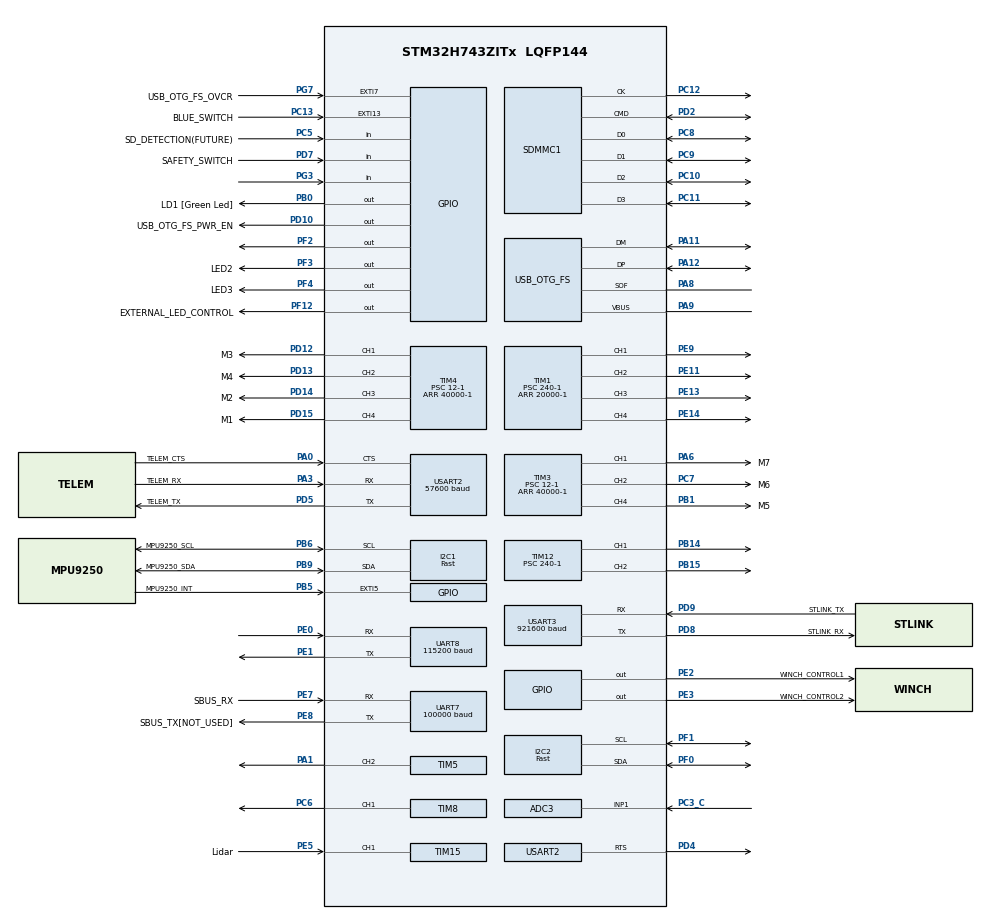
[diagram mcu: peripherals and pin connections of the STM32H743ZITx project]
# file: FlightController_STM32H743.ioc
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ADC3.Channel-1\#ChannelRegularConversion=ADC_CHANNEL_1
ADC3.ContinuousConvMode=ENABLE
ADC3.ConversionDataManagement=ADC_CONVERSIONDATA_DMA_CIRCULAR
ADC3.NbrOfConversionFlag=1
ADC3.OffsetNumber-1\#ChannelRegularConversion=ADC_OFFSET_NONE
ADC3.OffsetSignedSaturation-1\#ChannelRegularConversion=DISABLE
ADC3.Rank-1\#ChannelRegularConversion=1
ADC3.Resolution=ADC_RESOLUTION_12B
ADC3.SamplingTime-1\#ChannelRegularConversion=ADC_SAMPLETIME_1CYCLE_5
Bdma.ADC3.0.Direction=DMA_PERIPH_TO_MEMORY
Bdma.ADC3.0.EventEnable=DISABLE
Bdma.ADC3.0.Instance=BDMA_Channel0
Bdma.ADC3.0.MemDataAlignment=DMA_MDATAALIGN_HALFWORD
Bdma.ADC3.0.MemInc=DMA_MINC_ENABLE
Bdma.ADC3.0.Mode=DMA_CIRCULAR
Bdma.ADC3.0.PeriphDataAlignment=DMA_PDATAALIGN_HALFWORD
Bdma.ADC3.0.PeriphInc=DMA_PINC_DISABLE
Bdma.ADC3.0.Polarity=HAL_DMAMUX_REQ_GEN_RISING
Bdma.ADC3.0.Priority=DMA_PRIORITY_LOW
Bdma.ADC3.0.RequestNumber=1
Bdma.ADC3.0.SignalID=NONE
Bdma.ADC3.0.SyncEnable=DISABLE
Bdma.ADC3.0.SyncPolarity=HAL_DMAMUX_SYNC_NO_EVENT
Bdma.ADC3.0.SyncRequestNumber=1
Bdma.ADC3.0.SyncSignalID=NONE
Bdma.Request0=ADC3
Bdma.RequestsNb=1
Dma.I2C1_RX.1.Direction=DMA_PERIPH_TO_MEMORY
Dma.I2C1_RX.1.EventEnable=DISABLE
Dma.I2C1_RX.1.FIFOMode=DMA_FIFOMODE_DISABLE
Dma.I2C1_RX.1.Instance=DMA1_Stream2
Dma.I2C1_RX.1.MemDataAlignment=DMA_MDATAALIGN_BYTE
Dma.I2C1_RX.1.MemInc=DMA_MINC_ENABLE
Dma.I2C1_RX.1.Mode=DMA_NORMAL
Dma.I2C1_RX.1.PeriphDataAlignment=DMA_PDATAALIGN_BYTE
Dma.I2C1_RX.1.PeriphInc=DMA_PINC_DISABLE
Dma.I2C1_RX.1.Polarity=HAL_DMAMUX_REQ_GEN_RISING
Dma.I2C1_RX.1.Priority=DMA_PRIORITY_LOW
Dma.I2C1_RX.1.RequestNumber=1
Dma.I2C1_RX.1.SignalID=NONE
Dma.I2C1_RX.1.SyncEnable=DISABLE
Dma.I2C1_RX.1.SyncPolarity=HAL_DMAMUX_SYNC_NO_EVENT
Dma.I2C1_RX.1.SyncRequestNumber=1
Dma.I2C1_RX.1.SyncSignalID=NONE
Dma.I2C1_TX.3.Direction=DMA_MEMORY_TO_PERIPH
Dma.I2C1_TX.3.EventEnable=DISABLE
Dma.I2C1_TX.3.FIFOMode=DMA_FIFOMODE_DISABLE
Dma.I2C1_TX.3.Instance=DMA1_Stream3
Dma.I2C1_TX.3.MemDataAlignment=DMA_MDATAALIGN_BYTE
Dma.I2C1_TX.3.MemInc=DMA_MINC_ENABLE
Dma.I2C1_TX.3.Mode=DMA_NORMAL
Dma.I2C1_TX.3.PeriphDataAlignment=DMA_PDATAALIGN_BYTE
Dma.I2C1_TX.3.PeriphInc=DMA_PINC_DISABLE
Dma.I2C1_TX.3.Polarity=HAL_DMAMUX_REQ_GEN_RISING
Dma.I2C1_TX.3.Priority=DMA_PRIORITY_LOW
Dma.I2C1_TX.3.RequestNumber=1
Dma.I2C1_TX.3.SignalID=NONE
Dma.I2C1_TX.3.SyncEnable=DISABLE
Dma.I2C1_TX.3.SyncPolarity=HAL_DMAMUX_SYNC_NO_EVENT
Dma.I2C1_TX.3.SyncRequestNumber=1
Dma.I2C1_TX.3.SyncSignalID=NONE
Dma.Request0=UART7_RX
Dma.Request1=I2C1_RX
Dma.Request2=UART8_RX
Dma.Request3=I2C1_TX
Dma.Request4=USART2_RX
Dma.Request5=USART2_TX
Dma.UART7_RX.0.Direction=DMA_PERIPH_TO_MEMORY
Dma.UART7_RX.0.EventEnable=DISABLE
Dma.UART7_RX.0.FIFOMode=DMA_FIFOMODE_DISABLE
Dma.UART7_RX.0.Instance=DMA1_Stream1
Dma.UART7_RX.0.MemDataAlignment=DMA_MDATAALIGN_BYTE
Dma.UART7_RX.0.MemInc=DMA_MINC_ENABLE
Dma.UART7_RX.0.Mode=DMA_CIRCULAR
Dma.UART7_RX.0.PeriphDataAlignment=DMA_PDATAALIGN_BYTE
Dma.UART7_RX.0.PeriphInc=DMA_PINC_DISABLE
Dma.UART7_RX.0.Polarity=HAL_DMAMUX_REQ_GEN_RISING
Dma.UART7_RX.0.Priority=DMA_PRIORITY_LOW
Dma.UART7_RX.0.RequestNumber=1
Dma.UART7_RX.0.SignalID=NONE
Dma.UART7_RX.0.SyncEnable=DISABLE
Dma.UART7_RX.0.SyncPolarity=HAL_DMAMUX_SYNC_NO_EVENT
Dma.UART7_RX.0.SyncRequestNumber=1
Dma.UART7_RX.0.SyncSignalID=NONE
Dma.UART8_RX.2.Direction=DMA_PERIPH_TO_MEMORY
Dma.UART8_RX.2.EventEnable=DISABLE
Dma.UART8_RX.2.FIFOMode=DMA_FIFOMODE_DISABLE
Dma.UART8_RX.2.Instance=DMA1_Stream0
Dma.UART8_RX.2.MemDataAlignment=DMA_MDATAALIGN_BYTE
Dma.UART8_RX.2.MemInc=DMA_MINC_ENABLE
Dma.UART8_RX.2.Mode=DMA_CIRCULAR
Dma.UART8_RX.2.PeriphDataAlignment=DMA_PDATAALIGN_BYTE
Dma.UART8_RX.2.PeriphInc=DMA_PINC_DISABLE
Dma.UART8_RX.2.Polarity=HAL_DMAMUX_REQ_GEN_RISING
Dma.UART8_RX.2.Priority=DMA_PRIORITY_LOW
Dma.UART8_RX.2.RequestNumber=1
Dma.UART8_RX.2.SignalID=NONE
Dma.UART8_RX.2.SyncEnable=DISABLE
Dma.UART8_RX.2.SyncPolarity=HAL_DMAMUX_SYNC_NO_EVENT
Dma.UART8_RX.2.SyncRequestNumber=1
Dma.UART8_RX.2.SyncSignalID=NONE
Dma.USART2_RX.4.Direction=DMA_PERIPH_TO_MEMORY
Dma.USART2_RX.4.EventEnable=DISABLE
Dma.USART2_RX.4.FIFOMode=DMA_FIFOMODE_DISABLE
Dma.USART2_RX.4.Instance=DMA1_Stream4
Dma.USART2_RX.4.MemDataAlignment=DMA_MDATAALIGN_BYTE
Dma.USART2_RX.4.MemInc=DMA_MINC_ENABLE
Dma.USART2_RX.4.Mode=DMA_NORMAL
Dma.USART2_RX.4.PeriphDataAlignment=DMA_PDATAALIGN_BYTE
Dma.USART2_RX.4.PeriphInc=DMA_PINC_DISABLE
Dma.USART2_RX.4.Polarity=HAL_DMAMUX_REQ_GEN_RISING
Dma.USART2_RX.4.Priority=DMA_PRIORITY_LOW
Dma.USART2_RX.4.RequestNumber=1
Dma.USART2_RX.4.SignalID=NONE
Dma.USART2_RX.4.SyncEnable=DISABLE
Dma.USART2_RX.4.SyncPolarity=HAL_DMAMUX_SYNC_NO_EVENT
Dma.USART2_RX.4.SyncRequestNumber=1
Dma.USART2_RX.4.SyncSignalID=NONE
Dma.USART2_TX.5.Direction=DMA_MEMORY_TO_PERIPH
Dma.USART2_TX.5.EventEnable=DISABLE
Dma.USART2_TX.5.FIFOMode=DMA_FIFOMODE_DISABLE
Dma.USART2_TX.5.Instance=DMA1_Stream5
Dma.USART2_TX.5.MemDataAlignment=DMA_MDATAALIGN_BYTE
Dma.USART2_TX.5.MemInc=DMA_MINC_ENABLE
Dma.USART2_TX.5.Mode=DMA_NORMAL
Dma.USART2_TX.5.PeriphDataAlignment=DMA_PDATAALIGN_BYTE
Dma.USART2_TX.5.PeriphInc=DMA_PINC_DISABLE
Dma.USART2_TX.5.Polarity=HAL_DMAMUX_REQ_GEN_RISING
Dma.USART2_TX.5.Priority=DMA_PRIORITY_LOW
Dma.USART2_TX.5.RequestNumber=1
Dma.USART2_TX.5.SignalID=NONE
Dma.USART2_TX.5.SyncEnable=DISABLE
Dma.USART2_TX.5.SyncPolarity=HAL_DMAMUX_SYNC_NO_EVENT
Dma.USART2_TX.5.SyncRequestNumber=1
Dma.USART2_TX.5.SyncSignalID=NONE
FATFS.BSP.number=1
FATFS0.BSP.STBoard=false
FATFS0.BSP.api=Unknown
FATFS0.BSP.i2caddr=0
FATFS0.BSP.instance=PC5
FATFS0.BSP.ip=GPIO
FATFS0.BSP.mode=Input
FATFS0.BSP.name=Detect_SDIO
FATFS0.BSP.solution=PC5
FREERTOS.Tasks01=defaultTask,24,128,StartDefaultTask,Default,NULL,Dynamic,NULL,NULL;MPU9250_Task,48,256,MPU9250_StartTask,As external,NULL,Static,MPU9250_TaskBuffer,MPU9250_TaskControlBlock;BME280_Task,48,256,BME280_StartTask,As external,NULL,Static,BME280_TaskBuffer,BME280_TaskControlBlock;IST8310_Task,48,256,IST8310_StartTask,As external,NULL,Static,IST8310_TaskBuffer,IST8310_TaskControlBlock;SD_Task,24,2048,SD_StartTask,As external,NULL,Static,SD_TaskBuffer,SD_TaskControlBlock;AHRS_Task,48,256,AHRS_StartTask,As external,NULL,Static,AHRS_TaskBuffer,AHRS_TaskControlBlock;Commander_Task,48,256,Commander_StartTask,As external,NULL,Static,Commander_TaskBuffer,Commander_TaskControlBlock;Debug_Task,32,512,Debug_StartTask,As external,NULL,Dynamic,NULL,NULL;Buzzer_Task,32,256,Buzzer_StartTask,As external,NULL,Static,Buzzer_TaskBuffer,Buzzer_TaskControlBlock;Health_Task,48,512,Health_StartTask,As external,NULL,Static,Health_TaskBuffer,Health_TaskControlBlock;AC_Task,48,512,AC_StartTask,As external,NULL,Static,AC_TaskBuffer,AC_TaskControlBlock;INS_Task,47,2048,INS_StartTask,As external,NULL,Dynamic,NULL,NULL;PC_Task,47,1024,PC_StartTask,As external,NULL,Static,PC_TaskBuffer,PC_TaskControlBlock;GCS_Task,26,1024,GCS_StartTask,As external,NULL,Static,GCS_TaskBuffer,GCS_TaskControlBlock;AUTO_Task,47,1024,AUTO_StartTask,As external,NULL,Dynamic,NULL,NULL;SBUS_Task,48,512,SBUS_StartTask,As external,NULL,Static,SBUS_TaskBuffer,SBUS_TaskControlBlock;GPS_Task,48,512,GPS_StartTask,As external,NULL,Static,GPS_TaskBuffer,GPS_TaskControlBlock;MS4525D_Task,48,1024,MS4525D_StartTask,As external,NULL,Static,MS4525D_TaskBuffer,MS4525D_TaskControlBlock
FREERTOS.configTOTAL_HEAP_SIZE=30000
I2C1.I2C_Speed_Mode=I2C_Fast
I2C1.Timing=0x00B03FDB
I2C2.I2C_Speed_Mode=I2C_Fast
I2C2.Timing=0x00B03FDB
Mcu.Family=STM32H7
Mcu.Name=STM32H743ZITx
Mcu.Package=LQFP144
NVIC.ADC3_IRQn=true\:10\:0\:true\:false\:true\:true\:true\:true
NVIC.BDMA_Channel0_IRQn=true\:0\:0\:false\:false\:true\:true\:false\:true
NVIC.DMA1_Stream0_IRQn=true\:10\:0\:true\:false\:true\:true\:false\:true
NVIC.DMA1_Stream1_IRQn=true\:10\:0\:true\:false\:true\:true\:false\:true
NVIC.DMA1_Stream2_IRQn=true\:5\:0\:true\:false\:true\:true\:false\:true
NVIC.DMA1_Stream3_IRQn=true\:5\:0\:true\:false\:true\:true\:false\:true
NVIC.DMA1_Stream4_IRQn=true\:10\:0\:true\:false\:true\:true\:false\:true
NVIC.DMA1_Stream5_IRQn=true\:9\:0\:true\:false\:true\:true\:false\:true
NVIC.EXTI15_10_IRQn=true\:10\:0\:true\:false\:true\:false\:true\:true
NVIC.EXTI9_5_IRQn=true\:10\:0\:true\:false\:true\:false\:true\:true
NVIC.I2C1_ER_IRQn=true\:5\:0\:true\:false\:true\:false\:true\:true
NVIC.I2C1_EV_IRQn=true\:5\:0\:true\:false\:true\:false\:true\:true
NVIC.I2C2_ER_IRQn=true\:6\:0\:true\:false\:true\:false\:true\:true
NVIC.I2C2_EV_IRQn=true\:6\:0\:true\:false\:true\:false\:true\:true
NVIC.PriorityGroup=NVIC_PRIORITYGROUP_4
NVIC.SDMMC1_IRQn=true\:10\:0\:true\:false\:true\:false\:true\:true
NVIC.TIM15_IRQn=true\:0\:0\:false\:false\:true\:false\:true\:true
NVIC.TIM2_IRQn=true\:10\:0\:true\:false\:true\:false\:true\:true
NVIC.TIM6_DAC_IRQn=true\:0\:0\:false\:false\:true\:false\:false\:true
NVIC.TimeBase=TIM6_DAC_IRQn
NVIC.TimeBaseIP=TIM6
NVIC.UART7_IRQn=true\:10\:0\:true\:false\:true\:false\:true\:true
NVIC.UART8_IRQn=true\:8\:0\:true\:false\:true\:true\:true\:true
NVIC.USART2_IRQn=true\:10\:0\:true\:false\:true\:false\:true\:true
NVIC.USART3_IRQn=true\:0\:0\:false\:false\:true\:false\:true\:true
PA0.GPIO_Label=TELEM_CTS
PA0.Mode=CTS_RTS
PA0.Signal=USART2_CTS
PA1.Signal=S_TIM5_CH2
PA11.Mode=Device_Only
PA11.Signal=USB_OTG_FS_DM
PA12.Mode=Device_Only
PA12.Signal=USB_OTG_FS_DP
PA3.GPIO_Label=TELEM_RX
PA3.Mode=Asynchronous
PA3.Signal=USART2_RX
PA6.GPIO_Label=M7
PA6.Signal=S_TIM3_CH1
PA8.Mode=Activate_SOF_FS
PA8.Signal=USB_OTG_FS_SOF
PA9.Mode=Activate_VBUS
PA9.Signal=USB_OTG_FS_VBUS
PB0.GPIO_Label=LD1 [Green Led]
PB0.Signal=GPIO_Output
PB1.GPIO_Label=M5
PB1.Signal=S_TIM3_CH4
PB14.Signal=S_TIM12_CH1
PB15.Signal=S_TIM12_CH2
PB5.GPIO_Label=MPU9250_INT
PB5.GPIO_ModeDefaultEXTI=GPIO_MODE_IT_FALLING
PB5.GPIO_PuPd=GPIO_NOPULL
PB5.Signal=GPXTI5
PB6.GPIO_Label=MPU9250_SCL
PB6.Mode=I2C
PB6.Signal=I2C1_SCL
PB9.GPIO_Label=MPU9250_SDA
PB9.Mode=I2C
PB9.Signal=I2C1_SDA
PC10.GPIO_PuPd=GPIO_PULLUP
PC10.Mode=SD_4_bits_Wide_bus
PC10.Signal=SDMMC1_D2
PC11.GPIO_PuPd=GPIO_PULLUP
PC11.Mode=SD_4_bits_Wide_bus
PC11.Signal=SDMMC1_D3
PC12.Mode=SD_4_bits_Wide_bus
PC12.Signal=SDMMC1_CK
PC13.GPIO_Label=BLUE_SWITCH
PC13.Signal=GPXTI13
PC14-OSC32_IN\ (OSC32_IN).Mode=LSE-External-Clock-Source
PC14-OSC32_IN\ (OSC32_IN).Signal=RCC_OSC32_IN
PC3_C.Mode=IN1-Single-Ended
PC3_C.Signal=ADC3_INP1
PC5.GPIO_Label=SD_DETECTION(FUTURE)
PC5.Signal=GPIO_Input
PC6.Signal=S_TIM8_CH1
PC7.GPIO_Label=M6
PC7.Signal=S_TIM3_CH2
PC8.GPIO_PuPd=GPIO_PULLUP
PC8.Mode=SD_4_bits_Wide_bus
PC8.Signal=SDMMC1_D0
PC9.GPIO_PuPd=GPIO_PULLUP
PC9.Mode=SD_4_bits_Wide_bus
PC9.Signal=SDMMC1_D1
PD10.GPIO_Label=USB_OTG_FS_PWR_EN
PD10.Signal=GPIO_Output
PD12.GPIO_Label=M3
PD12.Signal=S_TIM4_CH1
PD13.GPIO_Label=M4
PD13.Signal=S_TIM4_CH2
PD14.GPIO_Label=M2
PD14.Signal=S_TIM4_CH3
PD15.GPIO_Label=M1
PD15.Signal=S_TIM4_CH4
PD2.GPIO_PuPd=GPIO_PULLUP
PD2.Mode=SD_4_bits_Wide_bus
PD2.Signal=SDMMC1_CMD
PD4.Mode=CTS_RTS
PD4.Signal=USART2_RTS
PD5.GPIO_Label=TELEM_TX
PD5.Mode=Asynchronous
PD5.Signal=USART2_TX
PD7.GPIO_Label=SAFETY_SWITCH
PD7.Signal=GPIO_Input
PD8.GPIO_Label=STLINK_RX
PD8.Mode=Asynchronous
PD8.Signal=USART3_TX
PD9.GPIO_Label=STLINK_TX
PD9.Mode=Asynchronous
PD9.Signal=USART3_RX
PE0.Mode=Asynchronous
PE0.Signal=UART8_RX
PE1.Mode=Asynchronous
PE1.Signal=UART8_TX
PE11.GPIO_Speed=GPIO_SPEED_FREQ_LOW
PE11.Signal=S_TIM1_CH2
PE13.Signal=S_TIM1_CH3
PE14.Signal=S_TIM1_CH4
PE2.GPIO_Label=WINCH_CONTROL1
PE2.Signal=GPIO_Output
PE3.GPIO_Label=WINCH_CONTROL2
PE3.Signal=GPIO_Output
PE5.GPIO_Label=Lidar
PE5.Signal=S_TIM15_CH1
PE7.GPIO_Label=SBUS_RX
PE7.Mode=Asynchronous
PE7.Signal=UART7_RX
PE8.GPIO_Label=SBUS_TX[NOT_USED]
PE8.Mode=Asynchronous
PE8.Signal=UART7_TX
PE9.Signal=S_TIM1_CH1
PF0.Mode=I2C
PF0.Signal=I2C2_SDA
PF1.Mode=I2C
PF1.Signal=I2C2_SCL
PF12.GPIO_Label=EXTERNAL_LED_CONTROL
PF12.Signal=GPIO_Output
PF2.Signal=GPIO_Output
PF3.GPIO_Label=LED2
PF3.Signal=GPIO_Output
PF4.GPIO_Label=LED3
PF4.Signal=GPIO_Output
PG3.Signal=GPIO_Input
PG7.GPIO_Label=USB_OTG_FS_OVCR
PG7.Signal=GPXTI7
PH0-OSC_IN\ (PH0).Mode=HSE-External-Oscillator
PH0-OSC_IN\ (PH0).Signal=RCC_OSC_IN
PH1-OSC_OUT\ (PH1).Mode=HSE-External-Oscillator
PH1-OSC_OUT\ (PH1).Signal=RCC_OSC_OUT
ProjectManager.HeapSize=0x200
ProjectManager.StackSize=0x400
ProjectManager.TargetToolchain=STM32CubeIDE
RCC.ADCFreq_Value=76000000
RCC.APB1Freq_Value=120000000
RCC.APB2Freq_Value=120000000
RCC.APB3Freq_Value=120000000
RCC.APB4Freq_Value=120000000
RCC.CortexFreq_Value=480000000
RCC.D1PPRE=RCC_APB3_DIV2
RCC.D2PPRE1=RCC_APB1_DIV2
RCC.D2PPRE2=RCC_APB2_DIV2
RCC.D3PPRE=RCC_APB4_DIV2
RCC.DIVM1=1
RCC.DIVM2=1
RCC.DIVN1=120
RCC.DIVN2=19
RCC.DIVQ1=20
RCC.HCLKFreq_Value=240000000
RCC.HPRE=RCC_HCLK_DIV2
RCC.HSE_VALUE=8000000
RCC.PLL2FRACN=0
RCC.PLL3FRACN=0
RCC.PLLFRACN=0
RCC.SYSCLKFreq_VALUE=480000000
RCC.SYSCLKSource=RCC_SYSCLKSOURCE_PLLCLK
RCC.USBFreq_Value=48000000
SDMMC1.ClockDiv=2
SH.S_TIM12_CH1.0=TIM12_CH1,PWM Generation1 CH1
SH.S_TIM12_CH2.0=TIM12_CH2,PWM Generation2 CH2
SH.S_TIM15_CH1.0=TIM15_CH1,Input_Capture1_from_TI1
SH.S_TIM15_CH1.1=TIM15_CH1,Input_Capture2_from_TI1
SH.S_TIM1_CH1.0=TIM1_CH1,PWM Generation1 CH1
SH.S_TIM1_CH2.0=TIM1_CH2,PWM Generation2 CH2
SH.S_TIM1_CH3.0=TIM1_CH3,PWM Generation3 CH3
SH.S_TIM1_CH4.0=TIM1_CH4,PWM Generation4 CH4
SH.S_TIM3_CH1.0=TIM3_CH1,PWM Generation1 CH1
SH.S_TIM3_CH2.0=TIM3_CH2,PWM Generation2 CH2
SH.S_TIM3_CH4.0=TIM3_CH4,PWM Generation4 CH4
SH.S_TIM4_CH1.0=TIM4_CH1,PWM Generation1 CH1
SH.S_TIM4_CH2.0=TIM4_CH2,PWM Generation2 CH2
SH.S_TIM4_CH3.0=TIM4_CH3,PWM Generation3 CH3
SH.S_TIM4_CH4.0=TIM4_CH4,PWM Generation4 CH4
SH.S_TIM5_CH2.0=TIM5_CH2,PWM Generation2 CH2
SH.S_TIM8_CH1.0=TIM8_CH1,PWM Generation1 CH1
TIM1.AutoReloadPreload=TIM_AUTORELOAD_PRELOAD_ENABLE
TIM1.Channel-PWM\ Generation1\ CH1=TIM_CHANNEL_1
TIM1.Channel-PWM\ Generation2\ CH2=TIM_CHANNEL_2
TIM1.Channel-PWM\ Generation3\ CH3=TIM_CHANNEL_3
TIM1.Channel-PWM\ Generation4\ CH4=TIM_CHANNEL_4
TIM1.OCFastMode_PWM-PWM\ Generation3\ CH3=TIM_OCFAST_DISABLE
TIM1.OCFastMode_PWM-PWM\ Generation4\ CH4=TIM_OCFAST_DISABLE
TIM1.Period=20000-1
TIM1.Prescaler=240-1
TIM12.AutoReloadPreload=TIM_AUTORELOAD_PRELOAD_ENABLE
TIM12.Channel-PWM\ Generation1\ CH1=TIM_CHANNEL_1
TIM12.Channel-PWM\ Generation2\ CH2=TIM_CHANNEL_2
TIM12.Period=20000-1
TIM12.Prescaler=240-1
TIM15.Channel-Input_Capture1_from_TI1=TIM_CHANNEL_1
TIM15.Channel-Input_Capture2_from_TI1=TIM_CHANNEL_2
TIM15.ICFilter_CH1=15
TIM15.ICPolarity_CH2=TIM_INPUTCHANNELPOLARITY_FALLING
TIM15.Period=65535-1
TIM15.Prescaler=240-1
TIM2.Prescaler=240-1
TIM3.AutoReloadPreload=TIM_AUTORELOAD_PRELOAD_DISABLE
TIM3.Channel-PWM\ Generation1\ CH1=TIM_CHANNEL_1
TIM3.Channel-PWM\ Generation2\ CH2=TIM_CHANNEL_2
TIM3.Channel-PWM\ Generation4\ CH4=TIM_CHANNEL_4
TIM3.OCFastMode_PWM-PWM\ Generation1\ CH1=TIM_OCFAST_DISABLE
TIM3.OCFastMode_PWM-PWM\ Generation2\ CH2=TIM_OCFAST_DISABLE
TIM3.OCFastMode_PWM-PWM\ Generation4\ CH4=TIM_OCFAST_DISABLE
TIM3.Period=40000-1
TIM3.Prescaler=12-1
TIM4.AutoReloadPreload=TIM_AUTORELOAD_PRELOAD_DISABLE
TIM4.Channel-PWM\ Generation1\ CH1=TIM_CHANNEL_1
TIM4.Channel-PWM\ Generation2\ CH2=TIM_CHANNEL_2
TIM4.Channel-PWM\ Generation3\ CH3=TIM_CHANNEL_3
TIM4.Channel-PWM\ Generation4\ CH4=TIM_CHANNEL_4
TIM4.OCFastMode_PWM-PWM\ Generation1\ CH1=TIM_OCFAST_DISABLE
TIM4.OCFastMode_PWM-PWM\ Generation2\ CH2=TIM_OCFAST_DISABLE
TIM4.OCFastMode_PWM-PWM\ Generation3\ CH3=TIM_OCFAST_DISABLE
TIM4.OCFastMode_PWM-PWM\ Generation4\ CH4=TIM_OCFAST_DISABLE
TIM4.Period=40000-1
TIM4.Prescaler=12-1
TIM5.Channel-PWM\ Generation2\ CH2=TIM_CHANNEL_2
TIM5.Period=10-1
TIM5.Prescaler=0
TIM5.Pulse-PWM\ Generation2\ CH2=5
TIM8.Channel-PWM\ Generation1\ CH1=TIM_CHANNEL_1
TIM8.Channel-PWM\ Generation2\ CH2=TIM_CHANNEL_2
TIM8.Period=40000-1
TIM8.Prescaler=12-1
UART7.BaudRate=100000
UART7.Parity=PARITY_EVEN
UART7.StopBits=UART_STOPBITS_2
UART7.WordLength=WORDLENGTH_9B
UART8.BaudRate=115200
USART2.BaudRate=57600
USART2.OverrunDisableParam=ADVFEATURE_OVERRUN_ENABLE
USART2.VirtualMode-Asynchronous=VM_ASYNC
USART3.BaudRate=921600
USART3.VirtualMode-Asynchronous=VM_ASYNC
USB_OTG_FS.VirtualMode=Device_Only
VP_FATFS_VS_SDIO.Mode=SDIO
VP_FREERTOS_VS_CMSIS_V2.Mode=CMSIS_V2
VP_SYS_VS_tim6.Mode=TIM6
VP_TIM1_VS_ClockSourceINT.Mode=Internal
VP_TIM2_VS_ClockSourceINT.Mode=Internal
VP_TIM3_VS_ClockSourceINT.Mode=Internal
VP_TIM4_VS_ClockSourceINT.Mode=Internal
VP_TIM5_VS_ClockSourceINT.Mode=Internal
VP_TIM8_VS_ClockSourceINT.Mode=Internal
board=NUCLEO-H743ZI2

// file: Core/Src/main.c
/* USER CODE BEGIN Header */
/**
  ******************************************************************************
  * @file           : main.c
  * @brief          : Main program body
  ******************************************************************************
  * @attention
  *
  * <h2><center>&copy; Copyright (c) 2020 STMicroelectronics.
  * All rights reserved.</center></h2>
  *
  * This software component is licensed by ST under Ultimate Liberty license
  * SLA0044, the "License"; You may not use this file except in compliance with
  * the License. You may obtain a copy of the License at:
  *                             www.st.com/SLA0044
  *
  ******************************************************************************
  */
/* USER CODE END Header */
#include "main.h"
#include "cmsis_os.h"
#include "adc.h"
#include "bdma.h"
#include "dma.h"
#include "fatfs.h"
#include "i2c.h"
#include "sdmmc.h"
#include "tim.h"
#include "usart.h"
#include "usb_otg.h"
#include "gpio.h"

/* USER CODE BEGIN Includes */
#include "Usec.h"
/* USER CODE END Includes */

void SystemClock_Config(void);
void MX_FREERTOS_Init(void);

int main(void)
{

  /* MCU Configuration--------------------------------------------------------*/

  /* Reset of all peripherals, Initializes the Flash interface and the Systick. */
  HAL_Init();

  /* Configure the system clock */
  SystemClock_Config();

  /* Initialize all configured peripherals */
  MX_GPIO_Init();
  MX_BDMA_Init();
  MX_DMA_Init();
  MX_USART3_UART_Init();
  MX_USB_OTG_FS_PCD_Init();
  MX_I2C1_Init();
  MX_I2C2_Init();
  MX_SDMMC1_SD_Init();
  MX_TIM3_Init();
  MX_TIM4_Init();
  MX_UART7_Init();
  MX_USART2_UART_Init();
  MX_FATFS_Init();
  MX_ADC3_Init();
  MX_TIM2_Init();
  MX_TIM1_Init();
  MX_UART8_Init();
  MX_TIM5_Init();
  MX_TIM8_Init();
  MX_TIM15_Init();
  MX_TIM12_Init();
  /* USER CODE BEGIN 2 */

  cppMain();
  /* USER CODE END 2 */

  /* Init scheduler */
  osKernelInitialize();  /* Call init function for freertos objects (in freertos.c) */
  MX_FREERTOS_Init();
  /* Start scheduler */
  osKernelStart();

  /* We should never get here as control is now taken by the scheduler */
  /* Infinite loop */
  while (1)
  {

  }
}

void SystemClock_Config(void)
{
  RCC_OscInitTypeDef RCC_OscInitStruct = {0};
  RCC_ClkInitTypeDef RCC_ClkInitStruct = {0};
  RCC_PeriphCLKInitTypeDef PeriphClkInitStruct = {0};

  /** Supply configuration update enable
  */
  HAL_PWREx_ConfigSupply(PWR_LDO_SUPPLY);
  /** Configure the main internal regulator output voltage
  */
  __HAL_PWR_VOLTAGESCALING_CONFIG(PWR_REGULATOR_VOLTAGE_SCALE0);

  while(!__HAL_PWR_GET_FLAG(PWR_FLAG_VOSRDY)) {}
  /** Macro to configure the PLL clock source
  */
  __HAL_RCC_PLL_PLLSOURCE_CONFIG(RCC_PLLSOURCE_HSE);
  /** Initializes the RCC Oscillators according to the specified parameters
  * in the RCC_OscInitTypeDef structure.
  */
  RCC_OscInitStruct.OscillatorType = RCC_OSCILLATORTYPE_HSE;
  RCC_OscInitStruct.HSEState = RCC_HSE_ON;
  RCC_OscInitStruct.PLL.PLLState = RCC_PLL_ON;
  RCC_OscInitStruct.PLL.PLLSource = RCC_PLLSOURCE_HSE;
  RCC_OscInitStruct.PLL.PLLM = 1;
  RCC_OscInitStruct.PLL.PLLN = 120;
  RCC_OscInitStruct.PLL.PLLP = 2;
  RCC_OscInitStruct.PLL.PLLQ = 20;
  RCC_OscInitStruct.PLL.PLLR = 2;
  RCC_OscInitStruct.PLL.PLLRGE = RCC_PLL1VCIRANGE_3;
  RCC_OscInitStruct.PLL.PLLVCOSEL = RCC_PLL1VCOWIDE;
  RCC_OscInitStruct.PLL.PLLFRACN = 0;
  if (HAL_RCC_OscConfig(&RCC_OscInitStruct) != HAL_OK)
  {
    Error_Handler();
  }
  /** Initializes the CPU, AHB and APB buses clocks
  */
  RCC_ClkInitStruct.ClockType = RCC_CLOCKTYPE_HCLK|RCC_CLOCKTYPE_SYSCLK
                              |RCC_CLOCKTYPE_PCLK1|RCC_CLOCKTYPE_PCLK2
                              |RCC_CLOCKTYPE_D3PCLK1|RCC_CLOCKTYPE_D1PCLK1;
  RCC_ClkInitStruct.SYSCLKSource = RCC_SYSCLKSOURCE_PLLCLK;
  RCC_ClkInitStruct.SYSCLKDivider = RCC_SYSCLK_DIV1;
  RCC_ClkInitStruct.AHBCLKDivider = RCC_HCLK_DIV2;
  RCC_ClkInitStruct.APB3CLKDivider = RCC_APB3_DIV2;
  RCC_ClkInitStruct.APB1CLKDivider = RCC_APB1_DIV2;
  RCC_ClkInitStruct.APB2CLKDivider = RCC_APB2_DIV2;
  RCC_ClkInitStruct.APB4CLKDivider = RCC_APB4_DIV2;

  if (HAL_RCC_ClockConfig(&RCC_ClkInitStruct, FLASH_LATENCY_4) != HAL_OK)
  {
    Error_Handler();
  }
  PeriphClkInitStruct.PeriphClockSelection = RCC_PERIPHCLK_USART3|RCC_PERIPHCLK_USART2
                              |RCC_PERIPHCLK_UART7|RCC_PERIPHCLK_UART8
                              |RCC_PERIPHCLK_SDMMC|RCC_PERIPHCLK_I2C2
                              |RCC_PERIPHCLK_ADC|RCC_PERIPHCLK_I2C1
                              |RCC_PERIPHCLK_USB;
  PeriphClkInitStruct.PLL2.PLL2M = 1;
  PeriphClkInitStruct.PLL2.PLL2N = 19;
  PeriphClkInitStruct.PLL2.PLL2P = 2;
  PeriphClkInitStruct.PLL2.PLL2Q = 2;
  PeriphClkInitStruct.PLL2.PLL2R = 2;
  PeriphClkInitStruct.PLL2.PLL2RGE = RCC_PLL2VCIRANGE_3;
  PeriphClkInitStruct.PLL2.PLL2VCOSEL = RCC_PLL2VCOMEDIUM;
  PeriphClkInitStruct.PLL2.PLL2FRACN = 0;
  PeriphClkInitStruct.SdmmcClockSelection = RCC_SDMMCCLKSOURCE_PLL;
  PeriphClkInitStruct.Usart234578ClockSelection = RCC_USART234578CLKSOURCE_D2PCLK1;
  PeriphClkInitStruct.I2c123ClockSelection = RCC_I2C123CLKSOURCE_D2PCLK1;
  PeriphClkInitStruct.UsbClockSelection = RCC_USBCLKSOURCE_PLL;
  PeriphClkInitStruct.AdcClockSelection = RCC_ADCCLKSOURCE_PLL2;
  if (HAL_RCCEx_PeriphCLKConfig(&PeriphClkInitStruct) != HAL_OK)
  {
    Error_Handler();
  }
  /** Enable USB Voltage detector
  */
  HAL_PWREx_EnableUSBVoltageDetector();
}

void HAL_TIM_PeriodElapsedCallback(TIM_HandleTypeDef *htim)
{
  /* USER CODE BEGIN Callback 0 */
	msOverFlow();
  /* USER CODE END Callback 0 */
  if (htim->Instance == TIM6) {
    HAL_IncTick();
  }
}

void Error_Handler(void)
{
}

/************************ (C) COPYRIGHT STMicroelectronics *****END OF FILE****/

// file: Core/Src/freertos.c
/* USER CODE BEGIN Header */
/**
  ******************************************************************************
  * File Name          : freertos.c
  * Description        : Code for freertos applications
  ******************************************************************************
  * @attention
  *
  * <h2><center>&copy; Copyright (c) 2020 STMicroelectronics.
  * All rights reserved.</center></h2>
  *
  * This software component is licensed by ST under Ultimate Liberty license
  * SLA0044, the "License"; You may not use this file except in compliance with
  * the License. You may obtain a copy of the License at:
  *                             www.st.com/SLA0044
  *
  ******************************************************************************
  */
/* USER CODE END Header */

#include "FreeRTOS.h"
#include "task.h"
#include "main.h"
#include "cmsis_os.h"

typedef StaticTask_t osStaticThreadDef_t;

/* Definitions for defaultTask */
osThreadId_t defaultTaskHandle;
const osThreadAttr_t defaultTask_attributes = {
  .name = "defaultTask",
  .priority = (osPriority_t) osPriorityNormal,
  .stack_size = 128 * 4
};
/* Definitions for MPU9250_Task */
osThreadId_t MPU9250_TaskHandle;
uint32_t MPU9250_TaskBuffer[ 256 ];
osStaticThreadDef_t MPU9250_TaskControlBlock;
const osThreadAttr_t MPU9250_Task_attributes = {
  .name = "MPU9250_Task",
  .stack_mem = &MPU9250_TaskBuffer[0],
  .stack_size = sizeof(MPU9250_TaskBuffer),
  .cb_mem = &MPU9250_TaskControlBlock,
  .cb_size = sizeof(MPU9250_TaskControlBlock),
  .priority = (osPriority_t) osPriorityRealtime,
};
/* Definitions for BME280_Task */
osThreadId_t BME280_TaskHandle;
uint32_t BME280_TaskBuffer[ 256 ];
osStaticThreadDef_t BME280_TaskControlBlock;
const osThreadAttr_t BME280_Task_attributes = {
  .name = "BME280_Task",
  .stack_mem = &BME280_TaskBuffer[0],
  .stack_size = sizeof(BME280_TaskBuffer),
  .cb_mem = &BME280_TaskControlBlock,
  .cb_size = sizeof(BME280_TaskControlBlock),
  .priority = (osPriority_t) osPriorityRealtime,
};
/* Definitions for IST8310_Task */
osThreadId_t IST8310_TaskHandle;
uint32_t IST8310_TaskBuffer[ 256 ];
osStaticThreadDef_t IST8310_TaskControlBlock;
const osThreadAttr_t IST8310_Task_attributes = {
  .name = "IST8310_Task",
  .stack_mem = &IST8310_TaskBuffer[0],
  .stack_size = sizeof(IST8310_TaskBuffer),
  .cb_mem = &IST8310_TaskControlBlock,
  .cb_size = sizeof(IST8310_TaskControlBlock),
  .priority = (osPriority_t) osPriorityRealtime,
};
/* Definitions for SD_Task */
osThreadId_t SD_TaskHandle;
uint32_t SD_TaskBuffer[ 2048 ];
osStaticThreadDef_t SD_TaskControlBlock;
const osThreadAttr_t SD_Task_attributes = {
  .name = "SD_Task",
  .stack_mem = &SD_TaskBuffer[0],
  .stack_size = sizeof(SD_TaskBuffer),
  .cb_mem = &SD_TaskControlBlock,
  .cb_size = sizeof(SD_TaskControlBlock),
  .priority = (osPriority_t) osPriorityNormal,
};
/* Definitions for AHRS_Task */
osThreadId_t AHRS_TaskHandle;
uint32_t AHRS_TaskBuffer[ 256 ];
osStaticThreadDef_t AHRS_TaskControlBlock;
const osThreadAttr_t AHRS_Task_attributes = {
  .name = "AHRS_Task",
  .stack_mem = &AHRS_TaskBuffer[0],
  .stack_size = sizeof(AHRS_TaskBuffer),
  .cb_mem = &AHRS_TaskControlBlock,
  .cb_size = sizeof(AHRS_TaskControlBlock),
  .priority = (osPriority_t) osPriorityRealtime,
};
/* Definitions for Commander_Task */
osThreadId_t Commander_TaskHandle;
uint32_t Commander_TaskBuffer[ 256 ];
osStaticThreadDef_t Commander_TaskControlBlock;
const osThreadAttr_t Commander_Task_attributes = {
  .name = "Commander_Task",
  .stack_mem = &Commander_TaskBuffer[0],
  .stack_size = sizeof(Commander_TaskBuffer),
  .cb_mem = &Commander_TaskControlBlock,
  .cb_size = sizeof(Commander_TaskControlBlock),
  .priority = (osPriority_t) osPriorityRealtime,
};
/* Definitions for Debug_Task */
osThreadId_t Debug_TaskHandle;
const osThreadAttr_t Debug_Task_attributes = {
  .name = "Debug_Task",
  .priority = (osPriority_t) osPriorityAboveNormal,
  .stack_size = 512 * 4
};
/* Definitions for Buzzer_Task */
osThreadId_t Buzzer_TaskHandle;
uint32_t Buzzer_TaskBuffer[ 256 ];
osStaticThreadDef_t Buzzer_TaskControlBlock;
const osThreadAttr_t Buzzer_Task_attributes = {
  .name = "Buzzer_Task",
  .stack_mem = &Buzzer_TaskBuffer[0],
  .stack_size = sizeof(Buzzer_TaskBuffer),
  .cb_mem = &Buzzer_TaskControlBlock,
  .cb_size = sizeof(Buzzer_TaskControlBlock),
  .priority = (osPriority_t) osPriorityAboveNormal,
};
/* Definitions for Health_Task */
osThreadId_t Health_TaskHandle;
uint32_t Health_TaskBuffer[ 512 ];
osStaticThreadDef_t Health_TaskControlBlock;
const osThreadAttr_t Health_Task_attributes = {
  .name = "Health_Task",
  .stack_mem = &Health_TaskBuffer[0],
  .stack_size = sizeof(Health_TaskBuffer),
  .cb_mem = &Health_TaskControlBlock,
  .cb_size = sizeof(Health_TaskControlBlock),
  .priority = (osPriority_t) osPriorityRealtime,
};
/* Definitions for AC_Task */
osThreadId_t AC_TaskHandle;
uint32_t AC_TaskBuffer[ 512 ];
osStaticThreadDef_t AC_TaskControlBlock;
const osThreadAttr_t AC_Task_attributes = {
  .name = "AC_Task",
  .stack_mem = &AC_TaskBuffer[0],
  .stack_size = sizeof(AC_TaskBuffer),
  .cb_mem = &AC_TaskControlBlock,
  .cb_size = sizeof(AC_TaskControlBlock),
  .priority = (osPriority_t) osPriorityRealtime,
};
/* Definitions for INS_Task */
osThreadId_t INS_TaskHandle;
const osThreadAttr_t INS_Task_attributes = {
  .name = "INS_Task",
  .priority = (osPriority_t) osPriorityHigh7,
  .stack_size = 2048 * 4
};
/* Definitions for PC_Task */
osThreadId_t PC_TaskHandle;
uint32_t PC_TaskBuffer[ 1024 ];
osStaticThreadDef_t PC_TaskControlBlock;
const osThreadAttr_t PC_Task_attributes = {
  .name = "PC_Task",
  .stack_mem = &PC_TaskBuffer[0],
  .stack_size = sizeof(PC_TaskBuffer),
  .cb_mem = &PC_TaskControlBlock,
  .cb_size = sizeof(PC_TaskControlBlock),
  .priority = (osPriority_t) osPriorityHigh7,
};
/* Definitions for GCS_Task */
osThreadId_t GCS_TaskHandle;
uint32_t GCS_TaskBuffer[ 1024 ];
osStaticThreadDef_t GCS_TaskControlBlock;
const osThreadAttr_t GCS_Task_attributes = {
  .name = "GCS_Task",
  .stack_mem = &GCS_TaskBuffer[0],
  .stack_size = sizeof(GCS_TaskBuffer),
  .cb_mem = &GCS_TaskControlBlock,
  .cb_size = sizeof(GCS_TaskControlBlock),
  .priority = (osPriority_t) osPriorityNormal2,
};
/* Definitions for AUTO_Task */
osThreadId_t AUTO_TaskHandle;
const osThreadAttr_t AUTO_Task_attributes = {
  .name = "AUTO_Task",
  .priority = (osPriority_t) osPriorityHigh7,
  .stack_size = 1024 * 4
};
/* Definitions for SBUS_Task */
osThreadId_t SBUS_TaskHandle;
uint32_t SBUS_TaskBuffer[ 512 ];
osStaticThreadDef_t SBUS_TaskControlBlock;
const osThreadAttr_t SBUS_Task_attributes = {
  .name = "SBUS_Task",
  .stack_mem = &SBUS_TaskBuffer[0],
  .stack_size = sizeof(SBUS_TaskBuffer),
  .cb_mem = &SBUS_TaskControlBlock,
  .cb_size = sizeof(SBUS_TaskControlBlock),
  .priority = (osPriority_t) osPriorityRealtime,
};
/* Definitions for GPS_Task */
osThreadId_t GPS_TaskHandle;
uint32_t GPS_TaskBuffer[ 512 ];
osStaticThreadDef_t GPS_TaskControlBlock;
const osThreadAttr_t GPS_Task_attributes = {
  .name = "GPS_Task",
  .stack_mem = &GPS_TaskBuffer[0],
  .stack_size = sizeof(GPS_TaskBuffer),
  .cb_mem = &GPS_TaskControlBlock,
  .cb_size = sizeof(GPS_TaskControlBlock),
  .priority = (osPriority_t) osPriorityRealtime,
};
/* Definitions for MS4525D_Task */
osThreadId_t MS4525D_TaskHandle;
uint32_t MS4525D_TaskBuffer[ 1024 ];
osStaticThreadDef_t MS4525D_TaskControlBlock;
const osThreadAttr_t MS4525D_Task_attributes = {
  .name = "MS4525D_Task",
  .stack_mem = &MS4525D_TaskBuffer[0],
  .stack_size = sizeof(MS4525D_TaskBuffer),
  .cb_mem = &MS4525D_TaskControlBlock,
  .cb_size = sizeof(MS4525D_TaskControlBlock),
  .priority = (osPriority_t) osPriorityRealtime,
};

void StartDefaultTask(void *argument);
extern void MPU9250_StartTask(void *argument);
extern void BME280_StartTask(void *argument);
extern void IST8310_StartTask(void *argument);
extern void SD_StartTask(void *argument);
extern void AHRS_StartTask(void *argument);
extern void Commander_StartTask(void *argument);
extern void Debug_StartTask(void *argument);
extern void Buzzer_StartTask(void *argument);
extern void Health_StartTask(void *argument);
extern void AC_StartTask(void *argument);
extern void INS_StartTask(void *argument);
extern void PC_StartTask(void *argument);
extern void GCS_StartTask(void *argument);
extern void AUTO_StartTask(void *argument);
extern void SBUS_StartTask(void *argument);
extern void GPS_StartTask(void *argument);
extern void MS4525D_StartTask(void *argument);

void MX_FREERTOS_Init(void); /* (MISRA C 2004 rule 8.1) */

void MX_FREERTOS_Init(void) {

  /* Create the thread(s) */
  /* creation of defaultTask */
  defaultTaskHandle = osThreadNew(StartDefaultTask, NULL, &defaultTask_attributes);

  /* creation of MPU9250_Task */
  MPU9250_TaskHandle = osThreadNew(MPU9250_StartTask, NULL, &MPU9250_Task_attributes);

  /* creation of BME280_Task */
  BME280_TaskHandle = osThreadNew(BME280_StartTask, NULL, &BME280_Task_attributes);

  /* creation of IST8310_Task */
  IST8310_TaskHandle = osThreadNew(IST8310_StartTask, NULL, &IST8310_Task_attributes);

  /* creation of SD_Task */
  SD_TaskHandle = osThreadNew(SD_StartTask, NULL, &SD_Task_attributes);

  /* creation of AHRS_Task */
  AHRS_TaskHandle = osThreadNew(AHRS_StartTask, NULL, &AHRS_Task_attributes);

  /* creation of Commander_Task */
  Commander_TaskHandle = osThreadNew(Commander_StartTask, NULL, &Commander_Task_attributes);

  /* creation of Debug_Task */
  Debug_TaskHandle = osThreadNew(Debug_StartTask, NULL, &Debug_Task_attributes);

  /* creation of Buzzer_Task */
  Buzzer_TaskHandle = osThreadNew(Buzzer_StartTask, NULL, &Buzzer_Task_attributes);

  /* creation of Health_Task */
  Health_TaskHandle = osThreadNew(Health_StartTask, NULL, &Health_Task_attributes);

  /* creation of AC_Task */
  AC_TaskHandle = osThreadNew(AC_StartTask, NULL, &AC_Task_attributes);

  /* creation of INS_Task */
  INS_TaskHandle = osThreadNew(INS_StartTask, NULL, &INS_Task_attributes);

  /* creation of PC_Task */
  PC_TaskHandle = osThreadNew(PC_StartTask, NULL, &PC_Task_attributes);

  /* creation of GCS_Task */
  GCS_TaskHandle = osThreadNew(GCS_StartTask, NULL, &GCS_Task_attributes);

  /* creation of AUTO_Task */
  AUTO_TaskHandle = osThreadNew(AUTO_StartTask, NULL, &AUTO_Task_attributes);

  /* creation of SBUS_Task */
  SBUS_TaskHandle = osThreadNew(SBUS_StartTask, NULL, &SBUS_Task_attributes);

  /* creation of GPS_Task */
  GPS_TaskHandle = osThreadNew(GPS_StartTask, NULL, &GPS_Task_attributes);

  /* creation of MS4525D_Task */
  MS4525D_TaskHandle = osThreadNew(MS4525D_StartTask, NULL, &MS4525D_Task_attributes);

}

void StartDefaultTask(void *argument)
{
  for(;;)
  {
    osDelay(1);
  }
}

/************************ (C) COPYRIGHT STMicroelectronics *****END OF FILE****/
